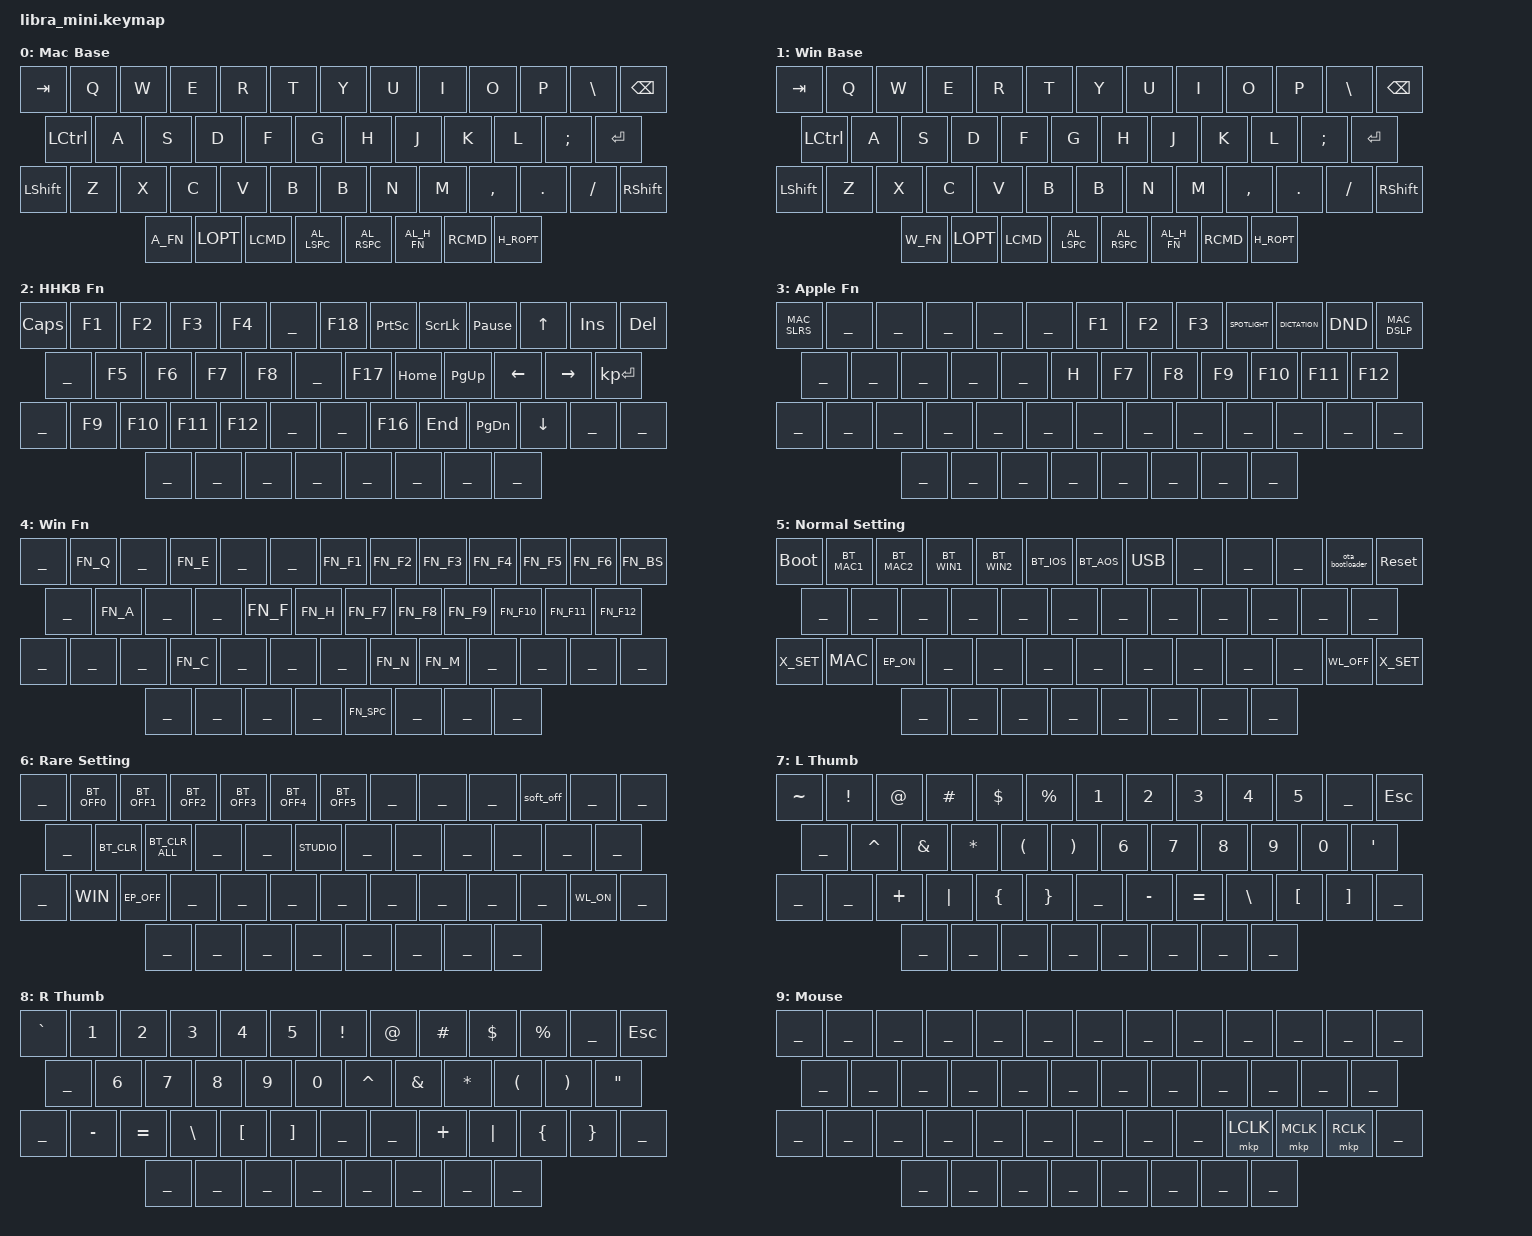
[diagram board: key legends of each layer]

/*
 * Copyright (c) 2020 The ZMK Contributors
 * SPDX-License-Identifier: MIT
 */

#include "my-keymap-common.dtsi"
#include <input/processors.dtsi>
#include <dt-bindings/zmk/pointing.h>
#include <dt-bindings/zmk/input_transform.h>

/*
 * Key positions
 *   Row 0 Left 0..5     Right 6..12
 *   Row 1 Left 13..18   Right 19..24
 *   Row 2 Left 25..30   Right 31..37
 *   Row 3 Left 38..41   Right 42..45
 */

#define MOUSE_KEYS 34 35 36
#define MODFIER_KEYS 15 25 37 38 39 40 43 44 45

/ {
  keymap {
    compatible = "zmk,keymap";

    mac_base_layer {
      display-name = "Mac Base";
      // --------------------------------------        -------------------------------------------
      // |  TAB |  Q  |  W  |  E  |  R  |  T  |        |  Y  |  U  |  I  |  O  |  P  |  \  |BKSP |
      // |  CTRL  |  A  |  S  |  D  |  F  |  G  |        |  H  |  J   |  K  |  L  |  ;  | ENTER  |
      // | SHFT    |  Z  |  X  |  C  |  V  |  B  |   |  B  |  N  |  M  |  ,  |  .  |  /  | SHIFT |
      // | fn🌐 | LOPT |      | LCMD |  ENT      |   |  SPC      | fn  | <joystick>  |RCMD |ROPT |
      // ---------------      --------------------   ---------------------------------------------
      bindings =
        <
         &kp TAB  &kp Q  &kp W  &kp E  &kp R    &kp T           &kp Y  &kp U  &kp I      &kp O    &kp P  &kp BSLH  &kp BSPC
         &kp LCTRL  &kp A  &kp S  &kp D  &kp F    &kp G           &kp H  &kp J  &kp K      &kp L    &kp SEMI       &kp ENTER
         &kp LSHFT     &kp Z  &kp X  &kp C  &kp V    &kp B   &kp B  &kp N  &kp M  &kp COMMA  &kp DOT  &kp FSLH     &kp RSHFT
         _A_FN    _LOPT              _LCMD     _AL_LSPC       _AL_RSPC    _AL_H_FN                    _RCMD        _H_ROPT
        >;
    };

    win_base_layer {
      display-name = "Win Base";
      // --------------------------------------        -------------------------------------------
      // |  TAB |  Q  |  W  |  E  |  R  |  T  |        |  Y  |  U  |  I  |  O  |  P  |  \  |BKSP |
      // |  CTRL  |  A  |  S  |  D  |  F  |  G  |        |  H  |  J   |  K  |  L  |  ;  | ENTER  |
      // | SHFT    |  Z  |  X  |  C  |  V  |  B  |   |  B  |  N  |  M  |  ,  |  .  |  /  | SHIFT |
      // | fn🌐 | LOPT |      | LCMD |  ENT      |   |  SPC      | fn  | <joystick>  |RCMD |ROPT |
      // ---------------      --------------------   -------------------             -------------
      bindings =
        <
         &kp TAB  &kp Q  &kp W  &kp E  &kp R    &kp T           &kp Y  &kp U  &kp I      &kp O    &kp P  &kp BSLH  &kp BSPC
         &kp LCTL   &kp A  &kp S  &kp D  &kp F    &kp G           &kp H  &kp J  &kp K      &kp L    &kp SEMI       &kp ENTER
         &kp LSHFT    &kp Z  &kp X  &kp C  &kp V    &kp B    &kp B  &kp N  &kp M  &kp COMMA  &kp DOT  &kp FSLH     &kp RSHFT
         _W_FN     _LOPT             _LCMD     _AL_LSPC       _AL_RSPC     _AL_H_FN                   _RCMD       _H_ROPT
        >;
    };

    hhkb_fn_layer {
      display-name = "HHKB Fn";
      // -------------------------------------        --------------------------------------------
      // | TAB | F1  | F2  | F3  | F4  |     |        | F18 |PSCRN|SLCK |PAUSE|  ↑   | INS | DEL |
      // |        | F5  | F6  | F7  | F8  |     |       | F17 |HOME |PG UP|  ←  |  →   |         |
      // |         | F9  | F10 | F11 | F12 |     |   |     | F16 | END |PG DN|  ↓  |      |      |
      // |      |      |      |      |           |   |           |     | <Joystick>  |     |     |
      // ---------------      --------------------   -------------------             --------------
      bindings =
        <
         &kp CAPS  &kp F1  &kp F2   &kp F3   &kp F4   ______            &kp F18  &kp PSCRN  &kp SLCK   &kp PAUSE_BREAK  &kp UP  &kp INS  &kp DEL
         ______      &kp F5  &kp F6   &kp F7   &kp F8   ______            &kp F17  &kp HOME   &kp PG_UP  &kp LEFT         &kp RIGHT      &kp KP_ENTER
         ______        &kp F9  &kp F10  &kp F11  &kp F12  ______    ______  &kp F16  &kp END    &kp PG_DN  &kp DOWN         ______       ______
         ______    ______               ______        ______            ______       ______                                 ______       ______
        >;
    };


    apple_fn_layer {
      display-name = "Apple Fn";
      // --------------------------------------        -------------------------------------------
      // |      |     |     |     |     |     |        |     |     |     |     |     |     |     |
      // |        |     |     |     |     |     |        |     |      |     |     |     |        |
      // |         |     |     |     |     |     |   |     |     |     |     |     |     |       |
      // |      |      |      |      |           |   |           |     | <Joystick>  |     |     |
      // ---------------      --------------------   -------------------             -------------
      bindings =
        <
         _MAC_SLRS ______  ______  ______  ______  ______            &kp F1   &kp F2  &kp F3  _SPOTLIGHT  _DICTATION  _DND  _MAC_DSLP
         ______      ______  ______  ______  ______  &kp H             &kp F7   &kp F8  &kp F9  &kp F10     &kp F11         &kp F12
         ______        ______  ______  ______  ______  ______     ______  ______  ______  ______  ______      ______        ______
         ______    ______              ______      ______             ______      ______                      ______        ______
        >;
    };

    win_fn_layer {
      display-name = "Win Fn";
      // --------------------------------------        -------------------------------------------
      // |      |     |     |     |     |     |        |     |     |     |     |     |     |     |
      // |        |     |     |     |     |     |        |     |      |     |     |     |        |
      // |         |     |     |     |     |     |   |     |     |     |     |     |     |       |
      // |      |      |      |      |           |   |           |     | <Joystick>  |     |     |
      // ---------------      --------------------   -------------------             -------------
      bindings =
        <
         ______  _FN_Q   ______  _FN_E   ______  ______             _FN_F1  _FN_F2  _FN_F3  _FN_F4   _FN_F5  _FN_F6  _FN_BS
         ______    _FN_A   ______  ______  _FN_F   _FN_H              _FN_F7  _FN_F8  _FN_F9  _FN_F10   _FN_F11     _FN_F12
         ______      ______  ______  _FN_C   ______  ______     ______  _FN_N   _FN_M   ______  ______    ______      ______
         ______  ______              ______      ______             _FN_SPC     ______                    ______      ______
        >;
    };

    normal_setting_layer {
      display-name = "Normal Setting";
      // --------------------------------------        -------------------------------------------
      // |      |     |     |     |     |     |        |     |     |     |     |     |     |     |
      // |        |     |     |     |     |     |        |     |      |     |     |     |        |
      // |         |     |     |     |     |     |   |     |     |     |     |     |     |       |
      // |      |      |      |      |           |   |           |     | <Joystick>  |     |     |
      // ---------------      --------------------   -------------------             -------------
      // ext-power is on by default for joystick
      bindings =
        <
         &bootloader  _BT_MAC1  _BT_MAC2  _BT_WIN1  _BT_WIN2  _BT_IOS          _BT_AOS  _USB    ______  ______  ______  &ota_bootloader  &sys_reset
         ______         ______    ______    ______    ______    ______           ______   ______  ______  ______  ______                 ______
         _X_SET           _MAC      _EP_ON    ______    ______    ______    ______  ______   ______  ______  ______  _WL_OFF             _X_SET
         ______       ______                     ______      ______              ______      ______                  ______              ______
        >;
    };

    rare_setting_layer {
      display-name = "Rare Setting";
      // --------------------------------------        -------------------------------------------
      // |      |     |     |     |     |     |        |     |     |     |     |     |     |     |
      // |        |     |     |     |     |     |        |     |      |     |     |     |        |
      // |         |     |     |     |     |     |   |     |     |     |     |     |     |       |
      // |      |      |      |      |           |   |           |     | <Joystick>  |     |     |
      // ---------------      --------------------   -------------------             -------------
      bindings =
        <
         ______  _BT_OFF0  _BT_OFF1  _BT_OFF2  _BT_OFF3  _BT_OFF4           _BT_OFF5  ______  ______  ______  &soft_off  ______  ______
         ______    _BT_CLR   _BT_CLR_ALL  ______    ______    _STUDIO          ______    ______  ______  ______  ______          ______
         ______      _WIN      _EP_OFF      ______    ______    ______    ______  ______    ______  ______  ______  _WL_ON       ______
         ______  ______                     ______         ______             ______         ______                 ______       ______
        >;
    };

    left_thumb_layer {
      display-name = "L Thumb";
      // --------------------------------------        -------------------------------------------
      // |  ~   |  !  |  @  |  #  |  $  |  %  |        |  1  |  2  |  3  |  4  |  5  |     | ESC |
      // |        |  ^  |  &  |  *  |  (  |  )  |        |  6  |  7  |  8  |  9  |  0  |   '     |
      // |         |  _  |  +  |  |  |  {  |  }  |   |     |  -  |  =  |  \  |  [  |  ]  |       |
      // |      |      |      |      |           |   |           |     | <Joystick>  |     |     |
      // ---------------      --------------------   -------------------             -------------
      bindings =
        <
         &kp TILDE  &kp EXCL   &kp AT    &kp HASH   &kp DLLR  &kp PRCNT           &kp N1     &kp N2     &kp N3     &kp N4    &kp N5    ______  &kp ESC
         ______       &kp CARET  &kp AMPS  &kp ASTRK  &kp LPAR  &kp RPAR            &kp N6     &kp N7     &kp N8     &kp N9    &kp N0          &kp SQT
         ______         &kp UNDER  &kp PLUS  &kp PIPE   &kp LBRC  &kp RBRC    ______  &kp MINUS  &kp EQUAL  &kp BSLH   &kp LBKT  &kp RBKT      ______
         ______     ______                   ______           ______              ______         ______                          ______        ______
        >;
    };

    right_thumb_layer {
      display-name = "R Thumb";
      // --------------------------------------        -------------------------------------------
      // |   `  |  1  |  2  |  3  |  4  |  5  |        |  !  |  @  |  #  |  $  |  %  |     | ESC |
      // |        |  6  |  7  |  8  |  9  |  0  |        |  ^  |  &   |  *  |  (  |  )  |   "    |
      // |         |  -  |  =  |  \  |  [  |  ]  |   |     |  _  |  +  |  |  |  {  |  }  |       |
      // |      |      |      |      |           |   |           |     | <Joystick>  |     |     |
      // ---------------      --------------------   -------------------             -------------
      bindings =
        <
         &kp GRAVE  &kp N1     &kp N2     &kp N3    &kp N4    &kp N5              &kp EXCL   &kp AT    &kp HASH   &kp DLLR  &kp PRCNT  ______  &kp ESC
         ______       &kp N6     &kp N7     &kp N8    &kp N9    &kp N0              &kp CARET  &kp AMPS  &kp ASTRK  &kp LPAR  &kp RPAR         &kp DQT
         ______         &kp MINUS  &kp EQUAL  &kp BSLH  &kp LBKT  &kp RBKT    ______  &kp UNDER  &kp PLUS  &kp PIPE   &kp LBRC  &kp RBRC       ______
         ______  ______                        ______         ______              ______         ______                         ______         ______
        >;
    };

    pointing_layer {
      display-name = "Mouse";
      // --------------------------------------        -------------------------------------------
      // |      |     |     |     |     |     |        |     |     |     |     |     |     |     |
      // |        |     |     |     |     |     |        |     |      |     |     |     |        |
      // |         |     |     |     |     |     |   |     |     |     |     |     |     |       |
      // |      |      |      |      |           |   |           |     | <Joystick>  |     |     |
      // ---------------      --------------------   -------------------             -------------
      bindings =
        <
         ______  ______  ______  ______  ______  ______           ______  ______  ______     ______      ______  ______  ______
         ______    ______  ______  ______  ______  ______           ______  ______  ______      ______     ______        ______
         ______      ______  ______  ______  ______  ______    ______  ______  ______  &mkp LCLK  &mkp MCLK  &mkp RCLK   ______
         ______  ______              ______       ______            ______     ______                        ______      ______
        >;
    };
  };
};


&zip_temp_layer {
  excluded-positions = <MOUSE_KEYS MODFIER_KEYS>;
};

&joystick_pointing_listener {
  input-processors
    = <&zip_xy_scaler 1 8>;

  win_scroller {
    layers = <_WIN_FN_LAYER>;
    input-processors
      = <&zip_xy_scaler 1 256>
      , <&zip_xy_transform INPUT_TRANSFORM_X_INVERT> /* natural scroll */
      , <&zip_xy_to_scroll_mapper>
      ;
  };

  mac_scroller {
    layers = <_APPLE_FN_LAYER>;
    input-processors
      = <&zip_xy_scaler 1 400>
      , <&zip_xy_transform INPUT_TRANSFORM_Y_INVERT> /* natural scroll */
      , <&zip_xy_to_scroll_mapper>
      ;
  };

  win_mouse {
    layers = <_WIN_BASE_LAYER>;
    input-processors
      = <&zip_xy_scaler 1 6>
      , <&zip_temp_layer _POINTING_LAYER 2000>;
  };

  /* TODO mouse speed difference between BLE and USB */
  mac_mouse {
    layers = <_MAC_BASE_LAYER>;
    input-processors
      = <&zip_xy_scaler 1 8>
      , <&zip_temp_layer _POINTING_LAYER 2000>;
  };
};
